# AT32A403A register map
Vendor: Keil; Series: AT32A403A; File version: 1.0
CPU: CM4 r0p1, little endian, no MPU, FPU, 4 interrupt priority bits
Registers are 32-bit, read-write, reset 0x0 unless marked. A register's access mark holds for its fields unless they carry their own. Offsets are from the block's base; [hi:lo] are bit positions; {n}, {i} and the like mark numbered series; 'fields as' and 'values as' point back to an identical list; <NAME> marks a mode.

## ETHERNET_DMA — Ethernet: DMA controller operation
Base 0x40029000
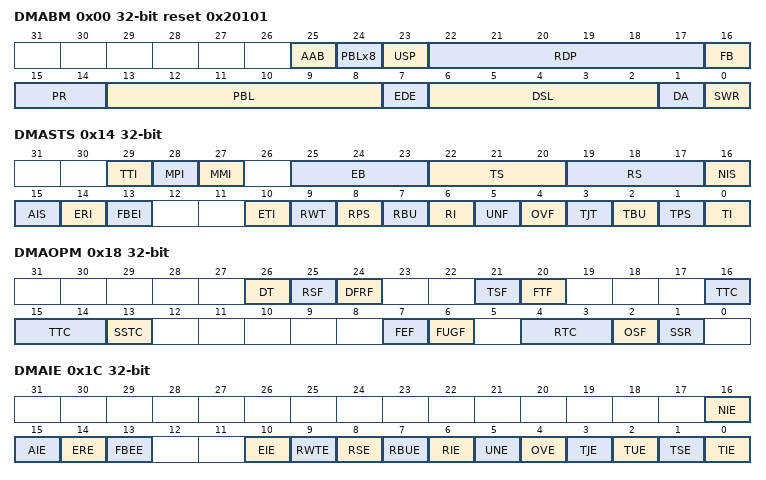
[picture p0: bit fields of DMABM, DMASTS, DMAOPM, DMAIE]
0x00 DMABM reset 0x20101 — Ethernet DMA bus mode register
  [25] AAB — Address-aligned beats
    0=Disabled (Address aligned beats disabled); 1=Enabled (Address aligned beats enabled. Applicable to GMAC only)
  [24] PBLx8 — PBLx8 mode
    0=Normal (Not multiply PBL value); 1=Mul8 (Multiply PBL value by 8 for the DMA burst length)
  [23] USP — Use separate PBL
    0=Shared (PBL value is applicable to both transmit and receive DMA); 1=Separate PBL value for transmit and receive DMA. RX uses RDB, TX uses PBL
  [22:17] RDP — Rx DMA PBL
  [16] FB — Fixed burst
    0=AllowIncr (Allow using INCR bursts for higher throughput); 1=OnlyFixed (Use only SINGLE/INCR4/INCR8/INCR16 bursts. The DMA does not use INCR burst transfers, making bus occupation more predictable)
  [15:14] PR — Priority ratio
    {v}=Ratio1_{v+1} (1:{v+1}) (v=0..3)
  [13:8] PBL — Programmable burst length
  [7] EDE — Enhanced descriptor enable
    0=Normal descriptor format; 1=Enhanced descriptor format, descriptor size increased to 8 words
  [6:2] DSL — Descriptor skip length
  [1] DA — DMA Arbitration
    0=Custom priority ratio between RX and TX. Controlled by PR; 1=FixedPriority (Tx has priority over Rx. Or otherwise, depending on bit 27 (TXPR))
  [0] SWR — Software reset
    on read: 0=NoReset (Software reset is not active); 1=Resetting (Software reset is active. This flag will be cleared when valid clocks are detected on appropriate pins) | on write: 0=NoReset; 1=StartReset (Begin reset. Set this bit to reset the DMA)
0x04 DMATPD wo — Ethernet DMA transmit poll demand register
  [31:0] TPD — Transmit poll demand
    0=Poll (When these bits are written with any value, the DMA reads the current descriptor pointed to by the EMAC_DMACTD. If the descriptor is not available (owned by host), the transmission suspends, and the bit 2 (TU) is set in the status register. If the descriptor is available, the transmission resumes.)
0x08 DMARPD wo — Ethernet DMA receive poll demand register
  [31:0] RPD — Receive poll demand
    0=Poll (When these bits are written with any value, the DMA reads the current descriptor pointed to by the EMAC_DMACRD. If the descriptor is not available (owned by host), the reception suspends, and the bit 7 (RU) is set in the status register. If the descriptor is available, the reception resumes.)
0x0C DMARDLADDR — Ethernet DMA receive descriptor list address register
0x10 DMATDLADDR — Ethernet DMA transmit descriptor list address register
0x14 DMASTS — Ethernet DMA status register
  [29] TTI ro — Timestamp trigger interrupt
    0=NoTimestampInterrupt; 1=Timestamp interrupt occurred
  [28] MPI ro — MAC PMT interrupt
    0=NoPmtInterrupt; 1=PMT interrupt occurred
  [27] MMI ro — MAC MMC interrupt
    0=NoMmcInterrupt; 1=MMC interrupt occurred
  [25:23] EB ro — Error bits
    0=RxDmaTransfer (Error during Rx DMA transfer); 3=TxDmaTransfer (Error during Tx DMA transfer); 4=RxDmaDescriptorWriteAccess (Error during write access to Rx DMA descriptor); 5=TxDmaDescriptorWriteAccess (Error during write access to Tx DMA descriptor); 6=RxDmaDescriptorReadAccess (Error during read access to Rx DMA descriptor); 7=TxDmaDescriptorReadAccess (Error during read access to Tx DMA descriptor)
  [22:20] TS ro — Transmit process state
    0=Stopped. Rest or Stop transmit command issued; 1=Running. Fetching receive descriptor; 2=Running. Waiting for status; 3=Running. Reading data from host memory buffer and queuing it to Tx FIFO; 4=Time stamp write status; 6=Suspended. Transmit descriptor unavailable or transmit buffer underflow; 7=Running. Closing transmit descriptor
  [19:17] RS ro — Receive process state
    0=Stopped. Rest or Stop transmit command issued; 1=Running. Fetching receive descriptor; 3=Running. Waiting for receive packet; 4=Suspended. Receive descriptor unavailable; 5=Running. Closing receive descriptor; 6=Time stamp write status; 7=Running. Transferring the receive buffer data to host memory
  [16] NIS write-1-clears — Normal interrupt summary
    on read: 0=NoInterrupt (No normal interrupt); 1=NormalInterrupt (TI | TBU | RI | ERI) | on write: 1=Clear this interrupt flag by writing 1 to it
  [15] AIS write-1-clears — Abnormal interrupt summary
    on read: 0=NoInterrupt (No abnormal interrupt); 1=AbnormalInterrupt (TPS | TJT | OVF | UNF | RBU | RPS | RWT | ETI | FBEI) | on write: 1=Clear this interrupt flag by writing 1 to it
  [14] ERI write-1-clears — Early receive interrupt
    on read: 0=NoInterrupt; 1=Interrupt occurred | on write: 1=Clear this interrupt flag by writing 1 to it
  [13] FBEI write-1-clears — Fatal bus error interrupt
    values as ERI
  [10] ETI write-1-clears — Early transmit interrupt
    values as ERI
  [9] RWT write-1-clears — Receive watchdog timeout
    values as ERI
  [8] RPS write-1-clears — Receive process stopped
    values as ERI
  [7] RBU write-1-clears — Receive buffer unavailable
    values as ERI
  [6] RI write-1-clears — Receive interrupt
    values as ERI
  [5] UNF write-1-clears — Transmit underflow
    values as ERI
  [4] OVF write-1-clears — Receive overflow
    values as ERI
  [3] TJT write-1-clears — Transmit jabber timeout
    values as ERI
  [2] TBU write-1-clears — Transmit buffer unavailable
    values as ERI
  [1] TPS write-1-clears — Transmit process stopped
    values as ERI
  [0] TI write-1-clears — Transmit interrupt
    values as ERI
0x18 DMAOPM — Ethernet DMA operation mode register
  [26] DT — Disable dropping of TCP/IP checksum error frames
    0=Normal operation; 1=DontDropErrorFrames (Don't drop frames with checksum errors in encapsulated payload. However ethernet checksum (FCS) must be valid)
  [25] RSF — Receive store and forward
    0=Disable (Receive store and forward disabled); 1=Enable (Receive store and forward enabled. The MTL reads the Rx FIFO only after a full frame is written to the Rx FIFO, ignoring the RTC bit)
  [24] DFRF — Disable flushing of received frames
    0=Normal operation, flush RX DMA if descriptors are unavailable; 1=DontFlush (Rx DMA does not flush any receive frame due to the unavailability of receive descriptors or receive buffers)
  [21] TSF — Transmit store and forward
    0=Disable (Transmit store and forward disabled); 1=Enable (Transmit store and forward enabled. Transmission starts when a full frame resides in the Tx FIFO, and the TTC values specified in the bit [16: 14] are ignored)
  [20] FTF write-1-sets — Flush transmit FIFO
    on write: 1=Flush the transmit FIFO. This bit is automatically cleared by hardware when the flush operation is completed
  [16:14] TTC — Transmit threshold control
    0=Thr64 (Threshold for short frames is 64 bytes); 1=Thr128 (Threshold for short frames is 128 bytes); 2=Thr192 (Threshold for short frames is 192 bytes); 3=Thr256 (Threshold for short frames is 256 bytes); 4=Thr40 (Threshold for short frames is 40 bytes); 5=Thr32 (Threshold for short frames is 32 bytes); 6=Thr24 (Threshold for short frames is 24 bytes); 7=Thr16 (Threshold for short frames is 16 bytes)
  [13] SSTC — Start of stop transmission command
    0=Stop (Transmit is stopped); 1=Start (Transmit is started or resumed)
  [7] FEF — Forward error frames
    0=Normal (Forward all frames except those with errors); 1=PassError (Forward all frames including those with CRC/collision/watchdog/overflow errors)
  [6] FUGF — Forward undersized good frames
    0=Normal (Drop frames less than 64 bytes); 1=PassUndersized (Forward undersized frames < 64 bytes if no error)
  [4:3] RTC — Receive threshold control
    0=Thr64 (Threshold for short frames is 64 bytes); 1=Thr32 (Threshold for short frames is 32 bytes); 2=Thr96 (Threshold for short frames is 96 bytes); 3=Thr128 (Threshold for short frames is 128 bytes)
  [2] OSF — Operate on second frame
    0=Normal (Operate on the first descriptor in the list of receive descriptors); 1=Next (Process second frame before status of first is obtained)
  [1] SSR — Start or stop receive
    0=Stop (Receive is stopped); 1=Start (Receive is started or resumed)
0x1C DMAIE — Ethernet DMA interrupt enable register
  [all] fields
    0=Disabled (Interrupt disabled); 1=Enabled (Interrupt enabled)
  [16] NIE — Normal interrupt enable
  [15] AIE — Abnormal interrupt enable
  [14] ERE — Early receive interrupt enable
  [13] FBEE — Fatal bus error enable
  [10] EIE — Early transmit interrupt enable
  [9] RWTE — receive watchdog timeout enable
  [8] RSE — Receive stopped enable
  [7] RBUE — Receive buffer unavailable enable
  [6] RIE — Receive interrupt enable
  [5] UNE — Underflow interrupt enable
  [4] OVE — Overflow interrupt enable
  [3] TJE — Transmit jabber timeout enable
  [2] TUE — Transmit buffer unavailable enable
  [1] TSE — Transmit stopped enable
  [0] TIE — Transmit interrupt enable
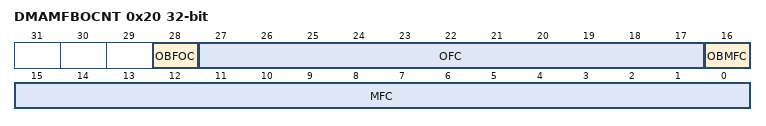
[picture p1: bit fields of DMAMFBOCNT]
0x20 DMAMFBOCNT ro — Ethernet DMA missed frame and buffer overflow counter register
  [28] OBFOC read-clears — Overflow bit for FIFO overflow counter
    0=No overflow of OFC field; 1=Overflow of OFC field. The OFC field is reset to 0 when this bit is set
  [27:17] OFC read-clears — Overflow frame counter
  [16] OBMFC read-clears — Overflow bit for missed frame counter
    0=No overflow of MFC field; 1=Overflow of MFC field. The MFC field is reset to 0 when this bit is set
  [15:0] MFC read-clears — Missed frames control
0x48 DMACTD ro — Ethernet DMA current host transmit descriptor register
0x4C DMACRD ro — Ethernet DMA current host receive descriptor register
0x50 DMACTBADDR ro — Ethernet DMA current host transmit buffer address register
0x54 DMACRBADDR ro — Ethernet DMA current host receive buffer address register
